# ESP32C6_RADIO register map
File version: 0.1.0
Registers are 32-bit, read-write, no defined reset value unless marked. A register's access mark holds for its fields unless they carry their own. Offsets are from the block's base; [hi:lo] are bit positions; {n}, {i} and the like mark numbered series; <NAME> marks a mode.

## I2C_ANA_MST — Analog I2C master `I2C_ANA_MST` at 0x600af800 is in the HAL; the register names are the HAL's.
Base 0x600AF800
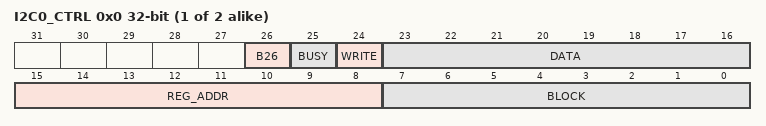
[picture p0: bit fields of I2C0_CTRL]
{0x0+4i} I2C{i}_CTRL (i=0..1) — Command word of master 0 and master 1 The ROM uses the same command word as the ESP32-S3: one command word per access, then poll I2C_ANA_MST_BUSY; block, register and I2C_ANA_MST_B26 for a read (0x04000000 base), plus data and I2C_ANA_MST_WRITE for a write (0x05000000 base). The result is in I2C_ANA_MST_DATA. Evidence: `modules/hal/espressif/components/soc/esp32c6/include/modem/i2c_ana_mst_reg.h:15-45`; *decompile* C6 ROM 0x40003d88
  [26] B26 — Unknown. The ROM sets it in every command word, as on the ESP32-S3; the HAL's own access code does not set it. Evidence: `modules/hal/espressif/components/esp_hal_regi2c/esp32c6/regi2c_impl.c:112-180`
  [25] BUSY ro — Busy; polled after each command word.
  [24] WRITE — Set for a write, clear for a read.
  [23:16] DATA — Data to write; after a read, the result.
  [15:8] REG_ADDR — Register number in the block.
  [7:0] BLOCK — Analog block id.
0x1C ANA_CONF1 — Read mask Other bits: documented Evidence: `modules/hal/espressif/components/soc/esp32c6/include/modem/i2c_ana_mst_reg.h:105-150`
  [23:0] ANA_CONF1 — The read mask.
0x20 ANA_CONF2 — Master select Other bits: documented Evidence: `modules/hal/espressif/components/soc/esp32c6/include/modem/i2c_ana_mst_reg.h:105-150`
  [23:0] ANA_CONF2 — The master select. The ROM's `get_i2c_hostid()` keeps the register's bits outside 17:4 and ORs in 0x1fe00. Evidence: *decompile* C6 ROM 0x40003d4a

## ULP — Analog I2C block 0x61 (ULP) Registers 0 to 10 at 2412 MHz: `1f 02 08 49 53 40 51 2f 33 59 20` (bench 2026-10-09). The Init rows below come from this dump.
Base 0x00006100
0x04 R4 8-bit — HAL `I2C_ULP_OCODE`, function undocumented Init: 0x53
  [7:0] OCODE — HAL name `I2C_ULP_OCODE`; the function is undocumented. Reads 0x4f instead of 0x53 after the native 802.15.4 radio ran in the previous firmware (see "Stale modem state"). Evidence: *measured* bench 2026-10-09; `modules/hal/espressif/components/soc/esp32c6/include/soc/regi2c_lp_bias.h:45`
0x09 R9 8-bit — Unknown Init: 0x59 Reads 0x5a in the same stale state as ULP_OCODE (see "Stale modem state"). Evidence: *measured* bench 2026-10-09

## RFPLL_SDM — Analog I2C block 0x63 (RF PLL fractional-N divider) Registers 0 and 3 to 6: `f_PLL = 1.5 * f_xtal * (32 + r3 + (r4 * 2^11 + r5 * 2^3 + r6[2:0]) / 2^19)` That is 60 MHz per integer step with the 40 MHz crystal. The vendor computes a word `W = r3 << 19 | r4 << 11 | r5 << 3 | r6` with `f_PLL = 3 * f_xtal * (16 + W / 2^20)`; W bit 27 is computed but not written. `write_rfpll_sdm()` clears RFPLL_SDM_R0_B3 (`0x63:0[3]`), writes registers 3 to 6 and sets the bit again. | PLL MHz | reg 3 | reg 4 | reg 5 | reg 6 | Note | |---|---|---|---|---|---| | 2412 | 0x08 | 0x33 | 0x33 | 0x01 | | | 2413 | 0x08 | 0x37 | 0x77 | 0x03 | | | 2417 | 0x08 | 0x48 | 0x88 | 0x04 | | | 2437 | 0x08 | 0x9d | 0xdd | 0x06 | | | 2438 | 0x08 | 0xa2 | 0x22 | 0x01 | | | 2280 | 0x06 | 0x00 | 0x00 | 0x00 | LO 1900 MHz through the divider | | 2404 | 0x08 | 0x11 | 0x11 | 0x00 | asked for 2412 MHz in the stale modem state | Evidence: *measured* bench 2026-10-09; *decompile* C6 ROM `write_rfpll_sdm` (0x400058ee), C6 `libphy.a` `phy_rfpll.o` (`ram_rfpll_set_freq`). The bench reading `60 MHz * (N + F / 2^20)` with N = 32 + reg 3 and `F = r4 << 12 | r5 << 4 | r6` is the same formula except that the vendor code weights reg 6 twice as much (it holds W bits 2:0), a difference below 0.2 kHz. The bench reading also took reg 3 as the low 4 bits of N; the vendor code puts 8 bits there (N - 32), which agrees for every value seen. The crystal selector of the vendor calls picks the divisor, as on the S3: 1 = 26 MHz, 2 = 32 MHz, anything else = 40 MHz (*decompile* C6 `ram_rfpll_set_freq`). The Init rows below are the values at 2412 MHz.
Base 0x00006300
0x00 R0 8-bit — Bit 3 cleared and set around a divider write; other bits unknown Init: 0x5b Evidence: *measured* bench 2026-10-09
  [3] R0_B3 — `write_rfpll_sdm()` clears it, writes RFPLL_SDM_R3 to RFPLL_SDM_R6 and sets it again. Evidence: *decompile* C6 ROM `write_rfpll_sdm` (0x400058ee)
0x01 R1 8-bit — Unknown Init: 0xab Evidence: *measured* bench 2026-10-09
0x03 R3 8-bit — Divider integer part Init: 0x08
  [7:0] INTEGER — r3 in the formula: N - 32. The vendor code puts 8 bits here.
0x04 R4 8-bit — Divider fraction, high byte Init: 0x33
  [7:0] FRAC_H — r4 in the formula.
0x05 R5 8-bit — Divider fraction, middle byte Init: 0x33
  [7:0] FRAC_M — r5 in the formula.
0x06 R6 8-bit — Divider fraction, low 3 bits Init: 0x01
  [2:0] FRAC_L — r6[2:0] in the formula: W bits 2:0.

## BBTOP — Analog I2C block 0x67 (BBTOP, analog baseband) The C6 libphy groups the filter codes as the S3 does (`filter_dcap_set()`: registers 4, 5, 12, 13 from one PHY parameter, 6, 7, 14, 15 from the next), so the transmit pairs are probably at the same place as on the S3 (*decompile* C6 `libphy.a` `phy_i2c.o`). `esp_sdr_tx_set_lpf()` returns -ENOTSUP on the C6. `esp_sdr_bbtop_read()` and `esp_sdr_bbtop_write()` give unchecked access (`lib/esp_sdr/src/esp_sdr_rx.c:689-708`).
Base 0x00006700
{0x0+i} R{i} (i=4..5) 8-bit — Receive low-pass capacitor code, I (BBTOP_R4) and Q (BBTOP_R5) Bits 7:6 are kept.
  [5:0] RX_LPF — Values 0 to 63; larger is narrower, 54 to 12 MHz on the C6. 0 is the widest setting, not a bypass. Evidence: *working* `lib/esp_sdr/src/esp_sdr_rx.c:126-148`; *upstream* curves `modules/lib/esp-sdr/main/common/rx_bandwidth.h:79-84`
{0x0+i} R{i} (i=12..13) 8-bit — Probably the transmit low-pass pair A, as on the S3 `filter_dcap_set()` writes them from the same PHY parameter as BBTOP_R4 and BBTOP_R5 (see the introduction). Evidence: *decompile* C6 `libphy.a` `phy_i2c.o`
{0x0+i} R{i} (i=14..15) 8-bit — Probably the transmit low-pass pair B, as on the S3 `filter_dcap_set()` writes them from the same PHY parameter as registers 6 and 7 (see the introduction). Evidence: *decompile* C6 `libphy.a` `phy_i2c.o`
